# MAX32550 register map
Vendor: Maxim Integrated; File version: 1.0
Registers are 32-bit, read-write, reset 0x0 unless marked. A register's access mark holds for its fields unless they carry their own. Offsets are from the block's base; [hi:lo] are bit positions; {n}, {i} and the like mark numbered series.

## I2C — Inter-Integrated Circuit
Base 0x4000C000; register names take the prefix I2C_
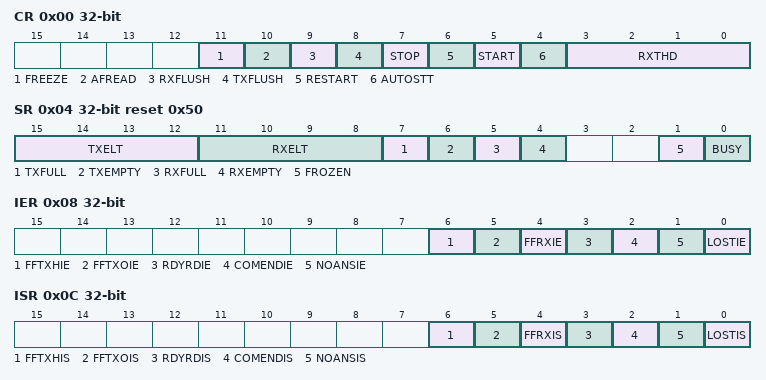
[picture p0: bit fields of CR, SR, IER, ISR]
0x00 CR — Control Register
  [11] FREEZE wo — Freeze. If set to 1, the I2C bus is frozen if the transmit FIFO is empty during a write or if the receive FIFO is full during a read.
    0=disable; 1=enable
  [10] AFREAD wo — Auto Read. If set to 1, this bit indicates that the current transfer should not be stopped but restarted when the transmit FIFO becomes empty (generally used to perform a read after a write transfer). The FREEZE bit should be set to prevent any error on the read operation. Use the I2C_ISR.RDYRDIS bit to know when you can write the slave address (in read mode) in the transmit FIFO.
    0=disable; 1=enable
  [9] RXFLUSH wo — Flush Receive FIFO. This bit is cleared by hardware.
    0=complete (No operation/complete); 1=Start operation
  [8] TXFLUSH — Flush Transmit FIFO. This bit is cleared by hardware.
    0=complete (No operation/complete); 1=Start operation
  [7] STOP — Stop Read communication. No effect on write communication.
    0=complete (No operation/complete); 1=Start operation
  [6] RESTART wo — Restart. When 1 is written, the communication restarts if the slave does not acknowledge the first byte (the address byte).
    0=complete (No operation/complete); 1=Start operation
  [5] START wo — Start communication. When 1 is written, I2C communication is started. This bit is automatically cleared by hardware when the first byte is sent.
    0=complete (No operation/complete); 1=Start operation
  [4] AUTOSTT — Auto Start. If this bit is 1, I2C communication starts automatically when a word is placed in the transmit FIFO.
    0=disable; 1=enable
  [3:0] RXTHD — Receive FIFO Threshold. This field specifies the depth of receive FIFO for interrupt generation.
    other=ignored (Reserved. Do not use.); 1=word1 (1 word); {v}=word{v} ({v} words) (v=2..8)
0x04 SR ro reset 0x50 — Status Register
  [15:12] TXELT — Number of byte in the TX FIFO
  [11:8] RXELT — Number of byte in the RX FIFO
  [7] TXFULL — Transmit FIFO Full
    0=notFull; 1=full
  [6] TXEMPTY — Transmit FIFO Empty
    0=notEmpty; 1=empty
  [5] RXFULL — Receive FIFO Full
    0=notFull; 1=full
  [4] RXEMPTY — Receive FIFO Empty
    0=notEmpty; 1=empty
  [1] FROZEN — Bus Frozen. This occurs when the clock signal is stuck at 0, such as being held by another device.
    0=notFrozen; 1=frozen
  [0] BUSY — Busy. The I2C Bus is busy when another master is using the bus or this interface itself is using the bus.
    0=idle; 1=busy
0x08 IER — Interrupt Enable Register
  [all] fields
    0=disable; 1=enable
  [6] FFTXHIE — Transmit FIFO Last Four Words Interrupt Enable
  [5] FFTXOIE — Transmit FIFO Last Word Interrupt Enable
  [4] FFRXIE — Receive FIFO Threshold Enable
  [3] RDYRDIE — Read Ready Interrupt Enable
  [2] COMENDIE — Communication End Interrupt Enable
  [1] NOANSIE — Address NACK (not acknowledge) Interrupt Enable
  [0] LOSTIE — Loss of Transfer Interrupt Enable
0x0C ISR — Interrupt Status Register
  [all] fields
    0=inactive (No interrupt is pending.); 1=pending (An interrupt is pending.)
  [6] FFTXHIS — Transmit FIFO Last Four Words Interrupt Status. This occurs when there are four bytes remaining in the TX FIFO.
  [5] FFTXOIS — Transmit FIFO Last Word Interrupt Status. This occurs when there is only one byte remaining in the TX FIFO.
  [4] FFRXIS — Receive FIFO Threshold Status. This occurs when FIFO RX reaches the programmed threshold.
  [3] RDYRDIS — Read Ready Interrupt Status. This occurs when the current write transfer is done and the next read is ready to be processed (only if AFREAD=1).
  [2] COMENDIS — Communication End Interrupt Status. This occurs when the current transfer is over.
  [1] NOANSIS — Address NACK (not acknowledge) Interrupt Status. This occurs when no slave responds to the address.
  [0] LOSTIS — Loss of Transfer Interrupt Status. This occurs when the current transfer is lost due to another master.
0x10 BRR 7-bit — Baud Rate Divisor. DIV = Nominal Frequency / (32 x Desired Frequency), where the nominal frequency = 2 x fPLL0.
0x14 RCR 16-bit — RX Count. Number of bytes to read. This register is used to specify how many bytes should be read from the device before stopping the communication.
0x18 TXR 8-bit — TX FIFO Output. This register is used to read the output of the FIFO, reading this register does not read the FIFO itself. This register is mainly used for debug purpose.
0x1C DR 8-bit — Data register. This register is used to obtain data from or place data into the FIFO. Read this register to retrieve the oldest data available in the RX FIFO. Write this register to place data in the TX FIFO.
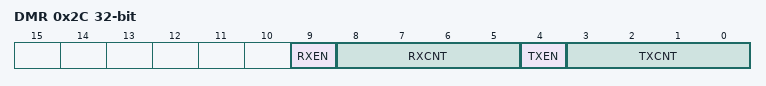
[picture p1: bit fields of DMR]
0x2C DMR — DMA Register
  [9] RXEN — RX channel enable
    0=disable; 1=enable
  [8:5] RXCNT — RX threshold
  [4] TXEN — TX channel enable
    0=disable; 1=enable
  [3:0] TXCNT — TX threshold
